# ET6801 register map
Vendor: ETMCU Inc.; File version: v0.0.1
CPU: CM7 r2p1, little endian, MPU, FPU, I-cache, D-cache, ITCM, DTCM, 4 interrupt priority bits
Registers are 32-bit, read-write, reset 0x0 unless marked. A register's access mark holds for its fields unless they carry their own. Offsets are from the block's base; [hi:lo] are bit positions; lines under a group give offsets from that group; {n}, {i} and the like mark numbered series.

## ADC0 — Provide an overview of the purpose and functionality of the peripheral: sarc_cfg
Base 0x40119000
Same registers: ADC1 0x4011A000, ADC2 0x4011B000
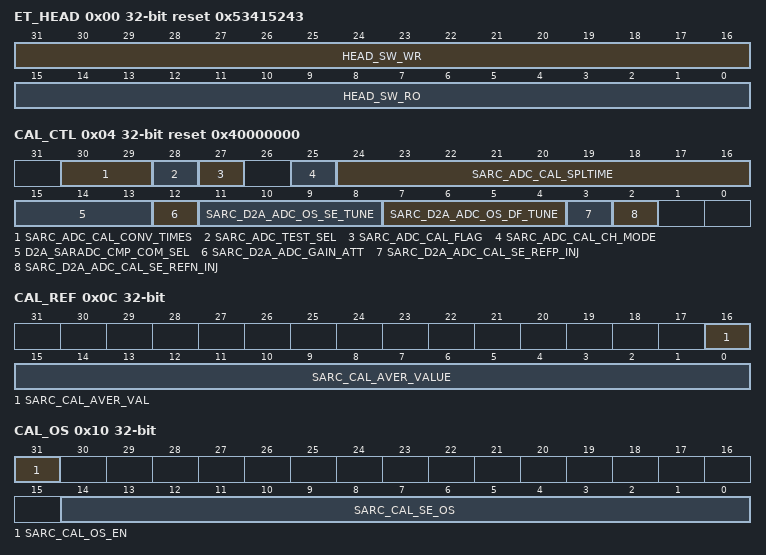
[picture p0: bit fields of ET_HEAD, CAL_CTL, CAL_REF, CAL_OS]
0x00 ET_HEAD reset 0x53415243
  [31:16] HEAD_SW_WR — 软件测试读写寄存器，硬件无访问
  [15:0] HEAD_SW_RO ro — 软件只读上报寄存器，硬件无访问,SARC的ASICII 码表示
0x04 CAL_CTL reset 0x40000000
  [30:29] SARC_ADC_CAL_CONV_TIMES — ADC校正时的模式选择。 'b00：1次转换结果上报； 'b01：8次转换结果平均后上报； 'b10：16次转换结果平均后上报； 'b11：32次转换结果平均后上报。
  [28] SARC_ADC_TEST_SEL — ADC测试模式选择。 'b 0：测试模式关闭 'b 1：测试模式打开，ADC测试模式包括（ADC测量模拟内部其他待观测节点电压，DAC校正时需要ADC对其输出信号检测等）
  [27] SARC_ADC_CAL_FLAG — ADC校正启动。此位由软件置1，用于开始ADC校准。在校正完成后，由软件置0。拉高该位后，再控制cfg_sarc_adc_cal_conv_start发起一轮校准采样。 'b 0：校准已完成。 'b 1：正在校准 ADC。
  [25] SARC_ADC_CAL_CH_MODE — 校正时，adccore的工作模式。 此位由软件置1和置0，用于配置校正时选择单端输入模式或差分输入模式。 0：单端输入模式。 1：差分输入模式。
  [24:16] SARC_ADC_CAL_SPLTIME — ADC CORE校正时，增加采样时长配置。ADCCLK时钟的周期计数。 配置值表示增加采样时长的时钟周期数；
  [15:13] D2A_SARADC_CMP_COM_SEL — SARADC0内部共模选择 3'b000：1.80V; 3'b001：1.65V; 3'b010：1.70V; 3'b011：1.75V; 3'b100：1.85V; 3'b101：1.90V; 3'b110：1.95V; 3'b111：2.00V;
  [12] SARC_D2A_ADC_GAIN_ATT — 配置ADC增益衰减为(1-32/4096)。 'b 0：默认ADC增益为1，即ADC输入为REFP-REFN时，输出为4096； 'b 1：使能校正时置为1，将ADC的增益衰减为(1-32/4096)。
  [11:8] SARC_D2A_ADC_OS_SE_TUNE — 配置单端模式下ADC offset模拟补偿值。 默认为全0，不做offset补偿。 1、Bit<3>为符号位，为1表示减，为0时表示加。 2、bit<2>对应8LSB，bit<1>对应4LSB，bit<0>对应2LSB。 3、例子： 0000/1000为加上或者减去0LSB。 1111为减去14LSB，0111为加上14LSB等等。
  [7:4] SARC_D2A_ADC_OS_DF_TUNE — 配置差分模式下ADC offset模拟补偿值。 默认为全0，不做offset补偿。 1、Bit<3>为符号位，为1表示减，为0时表示加。 2、bit<2>对应8LSB，bit<1>对应4LSB，bit<0>对应2LSB。 3、例子： 0000/1000为加上或者减去0LSB。 1111为减去14LSB，0111为加上14LSB等等。
  [3] SARC_D2A_ADC_CAL_SE_REFP_INJ — 控制ADC单端侧输入vrefp 默认为0，校正时配置为1，单端侧输入vrefp
  [2] SARC_D2A_ADC_CAL_SE_REFN_INJ — 控制ADC单端侧输入vrefn 默认为0，校正时配置为1，单端侧输入vrefn
0x08 CAL_CONV_CTL
  [0] SARC_ADC_CAL_CONV_START — 软件在校正转换参数配置完成后，启动转换。软件读返回0，软件写1启动转换。ADCCORE IDLE状态下，再cfg_sarc_adc_cal_flag 为高期间，拉高一次cfg_sarc_adc_cal_conv_start发起一轮ADC的转换。 'b 0：禁止校正转换； 'b 1：开始校正转换；
0x0C CAL_REF ro
  [16] SARC_CAL_AVER_VAL read-clears — 指示n次转换后的平均值有效。该寄存器在软件读取后自清零。 'b 0：平均值无效； 'b 1：平均值有效。
  [15:0] SARC_CAL_AVER_VALUE — n次转换后的平均值。S(16,2)。
0x10 CAL_OS
  [31] SARC_CAL_OS_EN — 数字域offset校正使能模块。 'b 0：数字域offset校正关闭。 'b 1：数字域offset校正打开。
  [14:0] SARC_CAL_SE_OS — 单端模式下数字域补偿的offset值，515bit有符号数，s(5,0) s(15,2) 精度1/4LSB。范围-16LSB---+15LSB
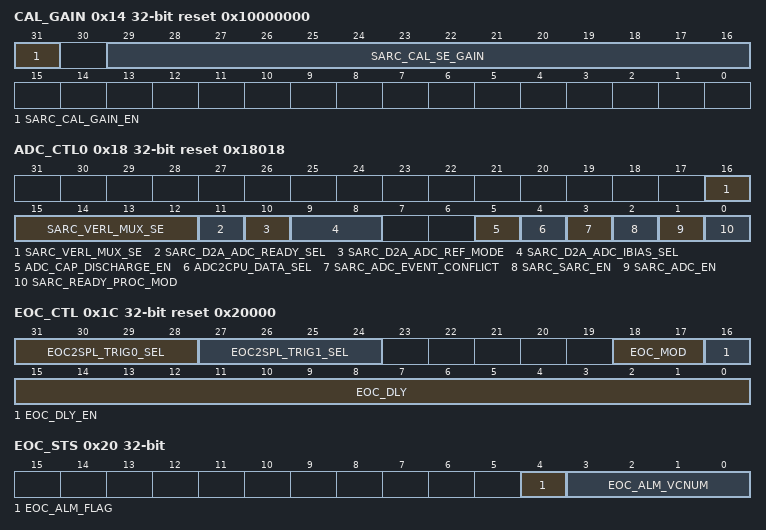
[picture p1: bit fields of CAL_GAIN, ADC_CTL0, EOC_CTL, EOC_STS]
0x14 CAL_GAIN reset 0x10000000
  [31] SARC_CAL_GAIN_EN — 数字域gain校正使能模块。 'b 0：数字域gain校正关闭。 'b 1：数字域gain校正打开。
  [29:16] SARC_CAL_SE_GAIN — 单端模式下数字域补偿的gain值，无符号数，u(14,12)
0x18 ADC_CTL0 reset 0x18018
  [16:12] SARC_VERL_MUX_SE — 放电过程中将mux切换到该值，使得模拟连接到VERFLO，默认0x18
  [11] SARC_D2A_ADC_READY_SEL — SARADC0 ready时序选择信号（模拟侧）， 1'b0：ready时序模拟顶层（AFE_TOP）对齐模式； 1'b1：ready时序模拟底层（ADC_CORE）对齐模式；
  [10] SARC_D2A_ADC_REF_MODE — SARADC参考电压模式选择 1'b0：参考电压为VREFHI（3.3V或2.5V），ADC输出摆幅为3.3V或2.5V; 1'b1：参考电压为1.65V，ADC输出摆幅为3.3V;
  [9:8] SARC_D2A_ADC_IBIAS_SEL — ADC bias电流调节 'b 00：5uA（默认值） 'b 01：3.75uA 'b 10：6.25uA 'b 11：7.5uA
  [5] ADC_CAP_DISCHARGE_EN — ADC启用放电功能配置 'b0:不启用放电功能； 'b1:启用放电功能；
  [4] ADC2CPU_DATA_SEL — adc内部同步到cpu_wrap的数据选择； 'b0：同步输出用户预处理通道结果到cpu_wrap 'b1：同步输出滤波通道结果到cpu_wrap
  [3] SARC_ADC_EVENT_CONFLICT — 事件冲突（多个虚拟通道同时触发采样）处理方式。 'b 0：低优先级任务被丢弃； 'b 1：低优先级任务排队处理。
  [2] SARC_SARC_EN — ADC控制器使能指示信号。 'b 0：ADC控制器不使能； 'b 1：ADC控制器使能。
  [1] SARC_ADC_EN — ADC core使能指示信号。 'b 0：ADC core不使能； 'b 1：ADC core使能。
  [0] SARC_READY_PROC_MOD — ADC READY处理模式选择配置（数字侧）。 'b 0：异步处理； 'b 1：同步处理。
0x1C EOC_CTL reset 0x20000
  [31:28] EOC2SPL_TRIG0_SEL — EOC事件输出1选择配置，从16个虚拟通道的EOC事件中选择1个作为ADC的采样触发源。 'd0：虚拟通道0的EOC事件； 'd1：虚拟通道1的EOC事件； ...... 'd15：虚拟通道15的EOC事件；
  [27:24] EOC2SPL_TRIG1_SEL — EOC事件输出2选择配置，从16个虚拟通道的EOC事件中选择1个作为ADC的采样触发源。 'd0：虚拟通道0的EOC事件； 'd1：虚拟通道1的EOC事件； ...... 'd15：虚拟通道15的EOC事件；
  [18:17] EOC_MOD — EOC产生时刻选择： 'b00：选择采样结束时刻，S/H窗口下降沿； 'b01：选择转换结束时刻，模拟ADC返回ready上升沿； 'b10: 选择采样开始时刻，S/H窗口上升沿,（内部状态仲裁出通道号后即给出，实际会比START信号早一点）； 'b11: reserved，同'b01；
  [16] EOC_DLY_EN — EOC选择时刻到中断上升沿是否延时的使能配置。 'b0：不使能延时，EOC时刻直接产生中断； 'b1：使能延时，在EOC时刻延时cfg_eoc_dly的SYSCLK周期后产生中断；
  [15:0] EOC_DLY — EOC选择时刻到中断上升沿的延时值配置，SYSCLK周期数。 实际延时值为该配置值加1，即cfg_eoc_dly+1。
0x20 EOC_STS ro
  [4] EOC_ALM_FLAG read-clears — 当eoc事件到达时，延时处理模块如果处于busy状态，则上报告警。 'b 0：无告警产生； 'b 1：有延时处理冲突告警；
  [3:0] EOC_ALM_VCNUM — 当eoc_alm_flag为高时，该域表示产生延时处理冲突的虚拟通道编号。 当eoc_alm_flag为低时，该域无效。 'd0~'d15对应表示虚拟通道0~15。
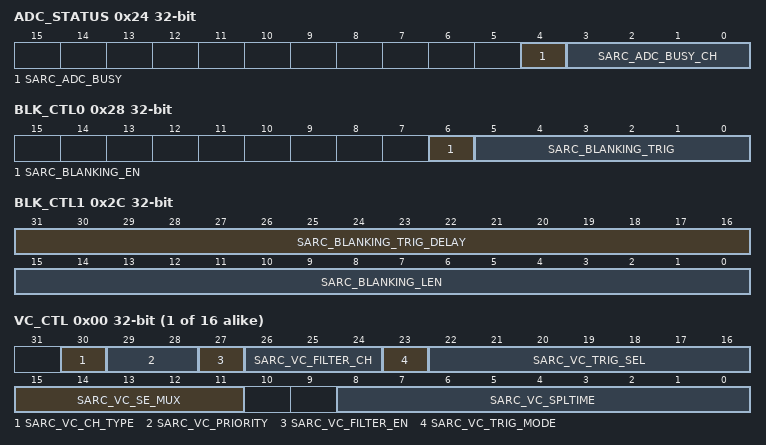
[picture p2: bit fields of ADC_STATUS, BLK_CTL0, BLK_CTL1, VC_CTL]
0x24 ADC_STATUS ro
  [4] SARC_ADC_BUSY — ADC采样busy状态。 ADC VC采样转换开始时置1，即busy； 虚拟通道VC采样转换完成后置0，即idle； 'b 0：IDLE； 'b 1：BUSY；
  [3:0] SARC_ADC_BUSY_CH — ADC busy通道指示。 adc_busy =0：保持上一个转换的VC通道号； adc_busy=1：指示当前正在转换操作的VC通道号；
0x28 BLK_CTL0
  [6] SARC_BLANKING_EN — ADC控制器的blanking功能使能标志。每个ADC控制器只有虚拟通道0（VC0）支持blanking管理功能。 'b 0：不使能； 'b 1：使能；
  [5:0] SARC_BLANKING_TRIG — ADC控制器的blanking触发源选择，该触发源触发blanking事件产生。Blanking支持64个触发源：
0x2C BLK_CTL1
  [31:16] SARC_BLANKING_TRIG_DELAY — ADC控制器的blanking延迟触发时间配置。SYSCLK时钟16bit计数器。配置值即为时钟周期数。 注意：在使能blanking功能时，该配置值需要大于0；
  [15:0] SARC_BLANKING_LEN — ADC控制器的blanking窗口长度配置。SYSCLK时钟16bit计数器。配置值即为时钟周期数。 注意： 1、在使能blanking功能时，该配置值需要大于0； 2、延迟时间和窗口长度配置时，需考虑将窗口提前打开，提前时间为一次转换时间。
0x30 VCEN_CTL
  [15:0] SARC_VC_EN — VC的使能信号,16bit分别表示16个VC的使能配置： 'b 0：不使能该VC； 'b 1：使能该VC；
{0x34+4i} VC_CTL[{i}] (i=0..15) group — CFG_SARC_VC_CTL
  0x00 VC_CTL
    [30] SARC_VC_CH_TYPE — VC采样通道类型选择： 0：单端模式； 1：差分模式；
    [29:28] SARC_VC_PRIORITY — VC的优先级指示。值越小优先级越高，同一优先级组中，VC的序号越小优先级越高。 'b 00：该VC处理第一优先级组； 'b 01：该VC处理第二优先级组； 'b 10：该VC处理第三优先级组； 'b 11：该VC处理第四优先级组；
    [27] SARC_VC_FILTER_EN — VC通道是否滤波。 'b 0：不滤波 'b 1：滤波
    [26:24] SARC_VC_FILTER_CH — VC通道与滤波通道的映射关系。 'b 000：映射滤波通道0； 'b 001：映射滤波通道1； ...... 'b 111：映射滤波通道7。
    [23] SARC_VC_TRIG_MODE — VCx的触发模式选择。支持One-Shot和Continuous两种触发模式。 'b 0：Continuous模式； 'b 1：One-Shot模式；
    [22:16] SARC_VC_TRIG_SEL — VCx的触发源选择。支持128个触发源选择。
    [15:11] SARC_VC_SE_MUX — VCx的单端转换通道选择。 'd0：通道0； 'd1：通道1； ...... 'd30：通道30； 'd31：通道31；
    [8:0] SARC_VC_SPLTIME — VCx的捕获预设。控制S/H增加的采样时间，支持0-256个ADCCLK周期数可配置。 实际的采样窗口总长度为：spltim+2.5UI
0x74 VC_STATUS ro
  [31:0] SARC_VC_STATUS — VC的状态指示。每2bit表示1个VC的状态，16个VC共需要32bit。 'b 00：idle； 'b 01：pending；当前VC处理排队等待状态。 'b 10：busy； 'b 11：无效状态RESERVED；
0x78 VC_FLAG ro
  [15:0] SARC_VC_FLAG — VCx待转换标志，在VC开始转换（start信号的上升沿）时硬件clear。 在同一cycle，如果set和clear同时有效，则响应set，因此ADC_VC_OVF寄存器的对应bit位不受影响。
0x7C VC_FORCE
  [15:0] SARC_VC_FORCE wo — VCx强制转换开始标志。该位写1会强制将ADC_VC_FLG寄存器的对应位置1，用于软件控制启动转换。该位写0无效，该位读返回为0。 在同一cycle，如果软件set此位，同时硬件clear ADC_VC_FLG寄存器的对应位，则ADC_VC_FLG寄存器对应位响应set，此时ADC_VC_OVF寄存器的对应bit位不受影响。
0x80 VC_OVF ro
  [15:0] SARC_VC_OVF — VCx转换溢出标志。指示VCx是否发生转换溢出事件。即当VCx正有待转换事件时，硬件又产生下一个转换事件。 该溢出指示不影响转换事件的处理，仅指明硬件触发的丢失。软件控制的ADC_VC_FRC对应位不影响该溢出标志位的值。
0x84 VC_OVF_CLR
  [15:0] SARC_VC_OVF_CLR wo — VCx清除转换溢出标志。 该位写1清除ADC_VC_OVF中对应位的溢出标志，该位写0无效。该位读返回0。 当软件置1该位的操作，与硬件置1 ADC_VC_OVF寄存器中的对应位的操作在同一个cycle发生时，硬件优先级高，即ADC_VC_OVF寄存器对应位会被置1。
0x88 T2S_FR_CNT ro
  [11:0] T2S_FR_CNT — FREE-RUN计数器，当cfg_sarc_en有效时计数。该计数器用于trig-to-sample的延时捕获计数。
{0x8C+8i} T2S_STAMP[{i}] (i=0..15) group
  0x00 REQ ro
    [11:0] REQSTAMP — 采样触发到达时刻的时间戳，在采样触发到达时刻锁存FR_CNT计数值。
  0x04 DLY ro
    [11:0] DLYSTAMP — trig-to-sample的延时时间戳。 使用采样开始时刻（S/H窗口上升沿）FR_CNT的计数值，减去采样触发时刻的时间戳reqstamp。 注意：FR_CNT最大计数为4096，当trig-to-sample的延时超过4096时，该dlystamp上报值可能是错误值，应用时要避免该情况出现。
0x10C PRE_OS_EN
  [15:0] SARC_PRE_OS_EN — 预处理阶段offset系数使能模块。bit15-0对应vc15-0。 'b 0：预处理阶段offset校正关闭。 'b 1：预处理阶段offset校正打开。
{0x110+4i} PRE_OS[{i}] (i=0..15) group — CFG_SARC_PRE_OS
  0x00 PRE_OS
    [15:0] SARC_PRE_OS — 预处理通道补偿的offset值，16bit有符号数s(16,2)。 配置限制范围：16'ha000~16'h6003
0x150 PRE_GAIN_EN
  [15:0] SARC_PRE_GAIN_EN — 预处理阶段gain系数使能模块。bit15-0对应vc15-0。 'b 0：预处理阶段offset校正关闭。 'b 1：预处理阶段offset校正打开。
{0x154+4i} PRE_GAIN[{i}] (i=0..15) group — CFG_SARC_PRE_GAIN
  0x00 PRE_GAIN reset 0x1000
    [14:0] SARC_PRE_GAIN — 预处理通道的gain值，15bit有符号数s(15,12)。
0x194 WDT_CTL
  [15:0] WDT_MOD — 16个超门限检测通道输出方式选择，bit0-bit15分别指示通道0-15。 'b 0：ONE-SHOT； 'b 1：CBC；
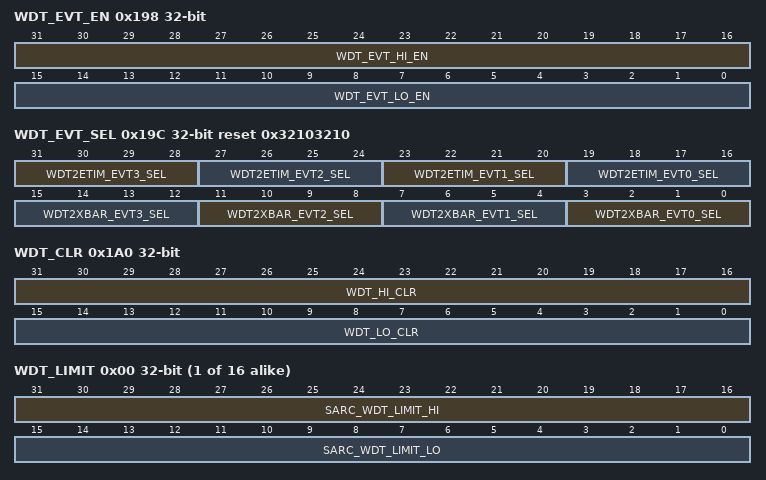
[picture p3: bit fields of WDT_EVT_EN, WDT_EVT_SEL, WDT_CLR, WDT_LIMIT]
0x198 WDT_EVT_EN
  [31:16] WDT_EVT_HI_EN — 16个超上门限事件输出使能，bit0-bit15分别指示通道0-15。 'b 0：不使能输出； 'b 1：使能输出；
  [15:0] WDT_EVT_LO_EN — 16个超下门限事件输出使能，bit0-bit15分别指示通道0-15。 'b 0：不使能输出； 'b 1：使能输出；
0x19C WDT_EVT_SEL reset 0x32103210
  [31:28] WDT2ETIM_EVT3_SEL — sarc2etim输出事件3的选择配置。 'd0~'d15：事件3输出选择虚拟通道0~15的事件；
  [27:24] WDT2ETIM_EVT2_SEL — sarc2etim输出事件2的选择配置。 'd0~'d15：事件22输出选择虚拟通道0~15的事件；
  [23:20] WDT2ETIM_EVT1_SEL — sarc2etim输出事件1的选择配置。 'd0~'d15：事件1输出选择虚拟通道0~15的事件；
  [19:16] WDT2ETIM_EVT0_SEL — sarc2etim输出事件0的选择配置。 'd0~'d15：事件0输出选择虚拟通道0~15的事件；
  [4n+3:4n] WDT2XBAR_EVT{n}_SEL (n=0..3) — sarc2xbar输出事件{n}的选择配置。 'd0~'d15：事件{n}输出选择虚拟通道0~15的事件；
0x1A0 WDT_CLR
  [31:16] WDT_HI_CLR wo — 16个超上门限状态清除指示，bit0-bit15分别指示通道0-15。 'b 0：无意义； 'b 1：产生清除脉冲；
  [15:0] WDT_LO_CLR wo — 16个超下门限状态清除指示，bit0-bit15分别指示通道0-15。 'b 0：无意义； 'b 1：产生清除脉冲；
{0x1A4+4i} WDT_LIMIT[{i}] (i=0..15) group — CFG_SARC_WDT_LIMIT
  0x00 WDT_LIMIT
    [31:16] SARC_WDT_LIMIT_HI — 预处理通道的WDT门限上限值。s(16,2)16bit有符号数
    [15:0] SARC_WDT_LIMIT_LO — 预处理通道的WDT门限下限值。s(16,2)16bit有符号数
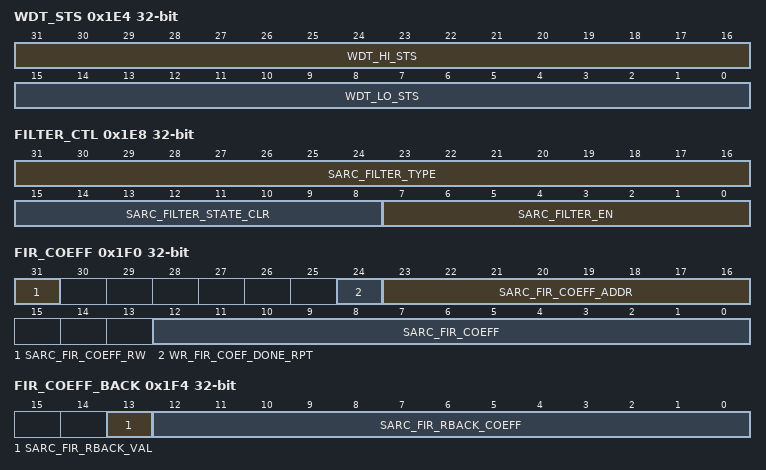
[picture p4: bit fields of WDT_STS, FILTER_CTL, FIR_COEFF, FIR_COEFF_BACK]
0x1E4 WDT_STS ro
  [31:16] WDT_HI_STS — 16个超上门限状态指示0-bit15分别指示通道0-15。 'b 0：无超上门限事件发生； 'b 1：有超上门限事件发生；
  [15:0] WDT_LO_STS — 16个超下门限状态指示，bit0-bit15分别指示通道0-15。 'b 0：无超下限事件发生； 'b 1：有超下限事件发生；
0x1E8 FILTER_CTL
  [31:16] SARC_FILTER_TYPE — 8个滤波通道类型选择，每个通道2bit表示类型选择。bit17-bit16指示滤波通道0的类型，...bit31-bit30指示滤波通道7的类型。 'b 00：FIR； 'b 01：IIR； 'b 10：非滑动平均； 'b 11：无效；
  [15:8] SARC_FILTER_STATE_CLR wo — 软件写1清除对应滤波通道状态，软件写0无效。bit15-bit8分别对应滤波通道7-滤波通道0。 建议在开启一轮新的滤波功能前，使用该控制位对滤波器进行清除，防止滤波历史残留数据对新数据的滤波产生影响。
  [7:0] SARC_FILTER_EN — 8个滤波通道使能信号，bit0-bit7分别指示滤波通道0-7。 'b 0：不使能； 'b 1：使能；
0x1EC NOAVER_COEFF
  [31:0] SARC_NOAVER_COEFF — 滤波通道7-0在非滑动平均滤波模式下的工作系数。每个通道4bit。 指示该滤波通道的平均次数：2^n ,n为该配置值。
0x1F0 FIR_COEFF
  [31] SARC_FIR_COEFF_RW — 软件操作滤波器系数的读写指示。 'b 0：write； 'b 1：read；
  [24] WR_FIR_COEF_DONE_RPT ro read-clears — 滤波器系数值配置完成上报信号。如果在滤波器通道工作过程中需要改变未使能的滤波通道的系数，该寄存器作为软件和硬件交互的接口，每次配置完成后软件需要读取该寄存器确定配置完成后，才能配置下一个系数。因为滤波器通道中读系数的优先级大于写系数的优先级。 'd0：滤波器系数没有配置，或者配置没有完成，或者配置完成被软件读清了 'd1：滤波器系数配置完成
  [23:16] SARC_FIR_COEFF_ADDR — 软件操作滤波器系数的地址数据。1个ADC控制器共有8组fir和iir滤波系数，FIR滤波器每组32个13bit有符号数s(13,12)，IIR滤波器每组1个13bit有符号数s(13,12)。 'b 000 00000-'b 000 11111：滤波通道0的FIR系数，共32个； 'b 001 00000-'b 001 11111：滤波通道1的FIR系数，共32个； 'b 010 00000-'b 010 11111：滤波通道2的FIR系数，共32个； 'b 011 00000-'b 011 11111：滤波通道3的FIR系数，共32个； 'b 100 00000-'b 100 11111：滤波通道4的FIR系数，共32个； 'b 101 00000-'b 101 11111：滤波通道5的FIR系数，共32个； 'b 110 00000-'b 110 11111：滤波通道6的FIR系数，共32个； 'b 111 00000-'b 111 11111：滤波通道7的FIR系数，共32个；
  [12:0] SARC_FIR_COEFF — 软件配置滤波器系数值，13bit有符号数。滤波系数固定为s(13,12)
0x1F4 FIR_COEFF_BACK ro
  [13] SARC_FIR_RBACK_VAL read-clears — 软件回读fir系数值有效指示。
  [12:0] SARC_FIR_RBACK_COEFF — 软件回读fir系数值，13bit有符号数。滤波系数固定为s(13,12)
{0x1F8+4i} FIR_LENGTH[{i}] (i=0..7) group — CFG_FIR_LENGTH
  0x00 FIR_LEN reset 0x1F
    [4:0] FIR_LEN — fir滤波器阶数配置，最大32阶。默认配置32阶。 'd0：1阶fir滤波； 'd1：2阶fir滤波； 'd2：3阶fir滤波； ...... 'd31：32阶fir滤波；
{0x218+4i} IIR_COEFF[{i}] (i=0..7) group — CFG_SARC_IIR_COEFF
  0x00 IIR_COEFF
    [12:0] SARC_IIR_COEFF — iir滤波器通道的滤波系数alpha，13bit有符号数s(13,12)，0 ≤ alpha ≤ 1
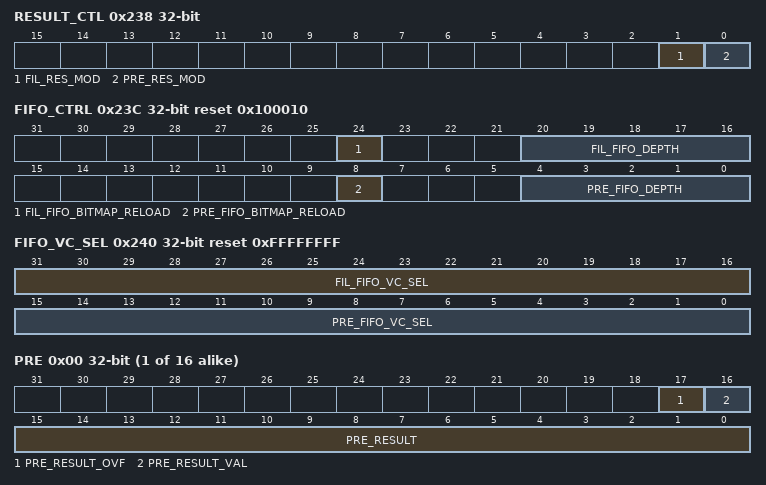
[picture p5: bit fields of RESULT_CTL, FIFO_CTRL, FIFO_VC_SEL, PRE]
0x238 RESULT_CTL
  [1] FIL_RES_MOD — ADC采样值滤波后上报结果寄存器格式配置： 'd0：u(12,0) 'd1：s(16,2)
  [0] PRE_RES_MOD — ADC采样值用户预处理后上报结果寄存器格式配置： 'd0：s(15,0)该数据由s(16,2)格式数据四舍五入后得到； 'd1：s(16,2)
0x23C FIFO_CTRL reset 0x100010
  [24] FIL_FIFO_BITMAP_RELOAD wo — ADC采样值滤波后上报结果采用fifo模式读取时，fifo读数据地址重新加载指示信号。在软件初始化或者重新配置vc_en/fifo_vc_sel后，需要向该bit位写1。 'b0：重新加载指示无效 'b1：重新加载指示有效
  [20:16] FIL_FIFO_DEPTH — ADC采样值滤波后上报结果采用fifo模式读取时，fifo的深度配置： 'd0：fifo深度为0，无效配置 'd1：fifo深度为1 'd2：fifo深度为2 ... 'd16：fifo深度为16 其它：无效配置
  [8] PRE_FIFO_BITMAP_RELOAD wo — ADC采样值用户预处理后上报结果采用fifo模式读取时，fifo读数据地址重新加载指示信号。在软件初始化或者重新配置vc_en/fifo_vc_sel后，需要向该bit位写1。 'b0：重新加载指示无效 'b1：重新加载指示有效
  [4:0] PRE_FIFO_DEPTH — ADC采样值用户预处理后上报结果采用fifo模式读取时，fifo的深度配置： 'd0：fifo深度为0，无效配置 'd1：fifo深度为1 'd2：fifo深度为2 ... 'd16：fifo深度为16 其它：无效配置
0x240 FIFO_VC_SEL reset 0xFFFFFFFF
  [31:16] FIL_FIFO_VC_SEL — ADC采样值滤波后上报结果采用fifo模式读取时，fifo映射vc选择配置，默认为全1，该配置与cfg_vc_en相与后作为最终的映射关系。如果使能的vc都映射到fifo时，该寄存器可以使用默认配置： 'b0：对应vc不映射到fifo模式 'b1：对应vc映射到fifo模式
  [15:0] PRE_FIFO_VC_SEL — ADC采样值用户预处理后上报结果采用fifo模式读取时，fifo映射vc选择配置，默认为全1，该配置与cfg_vc_en相与后作为最终的映射关系。如果使能的vc都映射到fifo时，该寄存器可以使用默认配置： 'b0：对应vc不映射到fifo模式 'b1：对应vc映射到fifo模式
0x244 FIL_FIFO_STS ro
  [31:0] FIL_FIFO_STS — ADC采样值滤波后上报结果采用fifo模式读取时，fifo的状态上报指示： bit0：fifo_full （fifo满） bit1：fifo_empty（fifo空） bit2：fifo_full_ovf（fifo满溢出） bit3：fifo_empty_ovf（fifo空溢出） bit4-bit8：fifo_data_cnt（fifo数据个数） 其它bit：无效
0x248 PRE_FIFO_STS ro
  [31:0] PRE_FIFO_STS — ADC采样值用户预处理后上报结果采用fifo模式读取时，fifo的状态上报指示： bit0：fifo_full （fifo满） bit1：fifo_empty（fifo空） bit2：fifo_full_ovf（fifo满溢出） bit3：fifo_empty_ovf（fifo空溢出） bit4-bit8：fifo_data_cnt（fifo数据个数） 其它bit：无效
0x24C FIL_FIFO_DATA ro
  [31:0] FIL_FIFO_DATA — ADC采样值滤波后上报结果采用fifo模式读取时，fifo的数据上报： bit0-bit15：采样结果 bit16：采样结果val值 bit17：采样结果ovf值 bit18-bit21：采样结果对应的vc编号 其它bit：无效
0x250 PRE_FIFO_DATA ro
  [31:0] PRE_FIFO_DATA — ADC采样值用户预处理后上报结果采用fifo模式读取时，fifo的数据上报： bit0-bit15：采样结果 bit16：采样结果val值 bit17：采样结果ovf值 bit18-bit21：采样结果对应的vc编号 其它bit：无效
{0x254+4i} PRE_RESULT[{i}] (i=0..15) group
  0x00 PRE
    [17] PRE_RESULT_OVF — VC采样结果寄存器有数据溢出指示。读清零。 每次有采样数据到达到，如果adc_result_val信号为高，则产生溢出指示。
    [16] PRE_RESULT_VAL — VC采样结果寄存器有数据指示。读清零。 每次该VC有采样数据，val信号置高。CPU或DMA读走后，置低。
    [15:0] PRE_RESULT ro — VC采样结果寄存器，s(15,0) (最高2位[15:14]均为符号位)或者s(16,2)
{0x294+4i} FIL_RESULT[{i}] (i=0..15) group
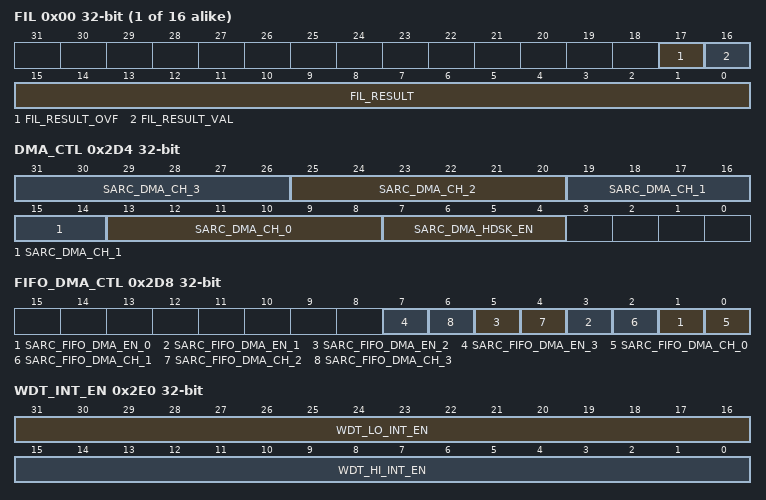
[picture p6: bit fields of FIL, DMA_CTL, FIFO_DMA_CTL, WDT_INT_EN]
  0x00 FIL
    [17] FIL_RESULT_OVF — VC采样结果寄存器有数据溢出指示。读清零。 每次有采样数据到达到，如果adc_result_val信号为高，则产生溢出指示。
    [16] FIL_RESULT_VAL — VC采样结果寄存器有数据指示。读清零。 每次该VC有采样数据，val信号置高。CPU或DMA读走后，置低。
    [15:0] FIL_RESULT ro — VC采样结果寄存器，u(12,0)或者s(16,2)
0x2D4 DMA_CTL
  [6n+13:6n+8] SARC_DMA_CH_{n} (n=0..3) — DMA通道{n}的选择。从64bit的DMA请求中选取1bit。 bit63-bit48：滤波后结果更新（vc15-vc0）； bit47-bit32：用户预处理后结果更新（vc15-vc0）； bit31-bit16：ADC超门限告警（超上下门限相或）（vc15-vc0）； bit15-bit0： ADC EOC（vc15-vc0）；
  [7:4] SARC_DMA_HDSK_EN — 4个DMA通道的握手模块使能信号。 'b 0：不使能； 'b 1：使能； 该使能信号不使用，DMA的握手功能移到DMA_MUX模块中。
0x2D8 FIFO_DMA_CTL
  [2n+1] SARC_FIFO_DMA_EN_{n} (n=0..3) — DMA通道{n}是否选择fifo请求使能配置 'b 0：不选择fifo请求，通道{n}的请求由CFG_SARC_DMA_CTL控制； 'b 1：选择fifo请求，由cfg_sarc_fifo_dma_ch_{n}选择相应的fifo请求；
  [2n] SARC_FIFO_DMA_CH_{n} (n=0..3) — DMA通道{n}选择fifo请求时，选择信号配置。只有cfg_sarc_fifo_dma_en_{n}为1时，才能选择对应的fifo请求到DMA通道{n}。 'b 0：选择pre_fifo的请求； 'b 1：选择fil_fifo的请求；
0x2DC EOC_INT_EN
  [3:0] EOC_INT_EN — ADC EOC中断使能信号，bit0~bit3分别表示eoc0~3 'b 0：不使能中断；'b 1：使能中断；
0x2E0 WDT_INT_EN
  [31:16] WDT_LO_INT_EN — ADC 采样超下门限中断使能信号，bit0~bit15分别表示虚拟通道0~15。 'b 0：不使能中断；'b 1：使能中断；
  [15:0] WDT_HI_INT_EN — ADC 采样超上门限中断使能信号，bit0~bit15分别表示虚拟通道0~15。 'b 0：不使能中断；'b 1：使能中断；
0x2E4 EOC_INT_MASK
  [3:0] EOC_INT_MASK — ADC 选择后EOC中断屏蔽信号，bit0~bit3分别表示eoc0~eoc3 'b 0：不屏蔽中断；'b 1：屏蔽中断；
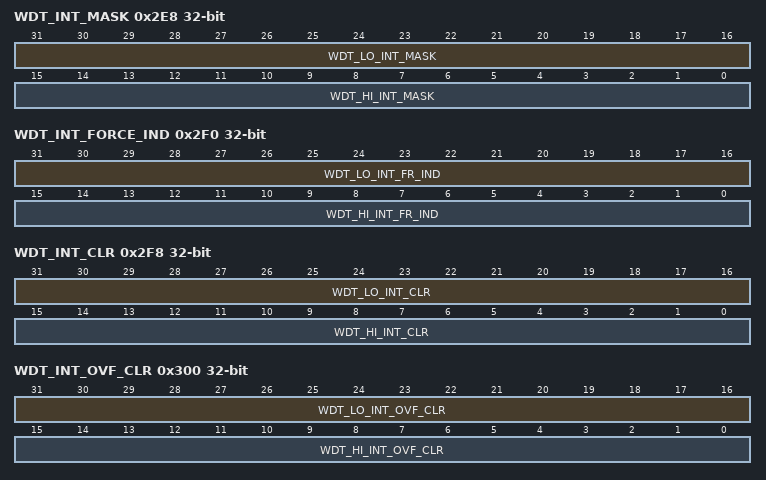
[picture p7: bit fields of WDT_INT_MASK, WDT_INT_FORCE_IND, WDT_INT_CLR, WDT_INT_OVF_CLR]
0x2E8 WDT_INT_MASK
  [31:16] WDT_LO_INT_MASK — ADC 采样超下门限中断屏蔽信号，bit0~bit15分别表示虚拟通道0~15。 'b 0：不屏蔽中断；'b 1：屏蔽中断；
  [15:0] WDT_HI_INT_MASK — ADC 采样超上门限中断屏蔽信号，bit0~bit15分别表示虚拟通道0~15。 'b 0：不屏蔽中断；'b 1：屏蔽中断；
0x2EC EOC_INT_FORCE_IND
  [3:0] EOC_INT_FR_IND — ADC EOC中断测试脉冲信号，bit0~bit3分别表示eoc0~eoc3 'b 0：不产生测试脉冲信号；'b 1：产生测试脉冲信号；
0x2F0 WDT_INT_FORCE_IND
  [31:16] WDT_LO_INT_FR_IND — ADC 采样超下门限中断测试脉冲信号，bit0~bit15分别表示虚拟通道0~15。 'b 0：不产生测试脉冲信号；'b 1：产生测试脉冲信号；
  [15:0] WDT_HI_INT_FR_IND — ADC 采样超上门限中断测试脉冲信号，bit0~bit15分别表示虚拟通道0~15。 'b 0：不产生测试脉冲信号；'b 1：产生测试脉冲信号；
0x2F4 EOC_INT_CLR
  [3:0] EOC_INT_CLR — ADC EOC中断清除脉冲信号，bit0~bit3分别表示eoc0~3 'b 0：不清除中断；'b 1：清除中断；
0x2F8 WDT_INT_CLR
  [31:16] WDT_LO_INT_CLR — ADC 采样超下门限中断清除脉冲信号，bit0~bit15分别表示虚拟通道0~15。 'b 0：不清除中断；'b 1：清除中断；
  [15:0] WDT_HI_INT_CLR — ADC 采样超上门限中断清除脉冲信号，bit0~bit15分别表示虚拟通道0~15。 'b 0：不清除中断；'b 1：清除中断；
0x2FC EOC_INT_OVF_CLR
  [3:0] EOC_INT_OVF_CLR — ADC EOC中断溢出指示清除脉冲信号，bit0~bit3分别表示虚拟通道eoc0~3 'b 0：不清除中断溢出指示；'b 1：清除中断溢出指示；
0x300 WDT_INT_OVF_CLR
  [31:16] WDT_LO_INT_OVF_CLR — ADC 采样超下门限中断溢出指示清除脉冲信号，bit0~bit15分别表示虚拟通道0~15。 'b 0：不清除中断溢出指示；'b 1：清除中断溢出指示；
  [15:0] WDT_HI_INT_OVF_CLR — ADC 采样超上门限中断溢出指示清除脉冲信号，bit0~bit15分别表示虚拟通道0~15。 'b 0：不清除中断溢出指示；'b 1：清除中断溢出指示；
0x304 EOC_INT_STS ro
  [3:0] EOC_INT_STS — ADC EOC中断状态指示（屏蔽后），bit0~bit3分别表示eoc0~3 'b 0：无中断指示；'b 1：有中断指示；
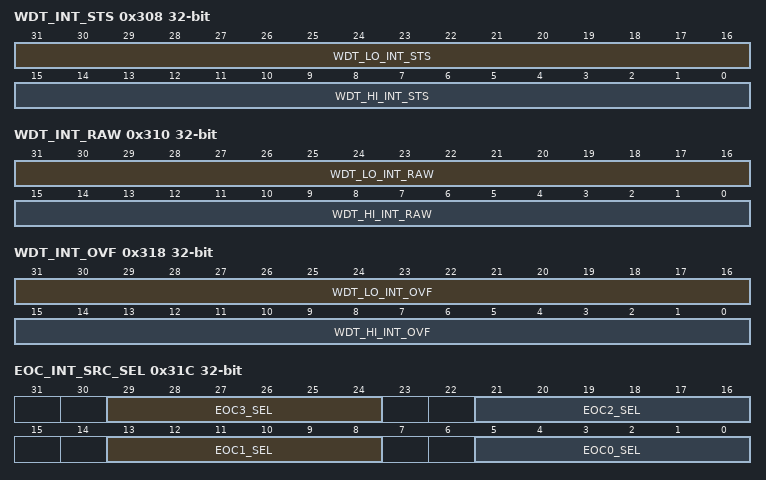
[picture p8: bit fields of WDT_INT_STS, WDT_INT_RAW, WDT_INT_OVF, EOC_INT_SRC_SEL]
0x308 WDT_INT_STS ro
  [31:16] WDT_LO_INT_STS — ADC 采样超下门限中断状态指示（屏蔽后），bit0~bit15分别表示虚拟通道0~15。 'b 0：无中断指示；'b 1：有中断指示；
  [15:0] WDT_HI_INT_STS — ADC 采样超上门限中断状态指示（屏蔽后），bit0~bit15分别表示虚拟通道0~15。 'b 0：无中断指示；'b 1：有中断指示；
0x30C EOC_INT_RAW ro
  [3:0] EOC_INT_RAW — ADC EOC中断原始状态指示（屏蔽前），bit0~bit3分别表示eoc0~3 'b 0：无中断指示；'b 1：有中断指示；
0x310 WDT_INT_RAW ro
  [31:16] WDT_LO_INT_RAW — ADC 采样超下门限中断原始状态指示（屏蔽前），bit0~bit15分别表示虚拟通道0~15。 'b 0：无中断指示；'b 1：有中断指示；
  [15:0] WDT_HI_INT_RAW — ADC 采样超上门限中断原始状态指示（屏蔽前），bit0~bit15分别表示虚拟通道0~15。 'b 0：无中断指示；'b 1：有中断指示；
0x314 EOC_INT_OVF ro
  [3:0] EOC_INT_OVF — ADC EOC中断溢出指示，bit0~bit3分别表示虚拟通道eoc0~3 'b 0：无中断溢出；'b 1：中断溢出；
0x318 WDT_INT_OVF ro
  [31:16] WDT_LO_INT_OVF — ADC 采样超下门限中断溢出指示，bit0~bit15分别表示虚拟通道0~15。 'b 0：无中断溢出；'b 1：中断溢出；
  [15:0] WDT_HI_INT_OVF — ADC 采样超上门限中断溢出指示，bit0~bit15分别表示虚拟通道0~15。 'b 0：无中断溢出；'b 1：中断溢出；
0x31C EOC_INT_SRC_SEL
  [29:24] EOC3_SEL — 选择eoc3的中断触发源，选择列表同cfg_eoc0_sel
  [21:16] EOC2_SEL — 选择eoc2的中断触发源，选择列表同cfg_eoc0_sel
  [13:8] EOC1_SEL — 选择eoc1的中断触发源，选择列表同cfg_eoc0_sel
  [5:0] EOC0_SEL — d0~'d15:选择eoc_out_p[0]~eoc_out_p[15]作为eoc0的中断源 'd16~'d31: 选择pre_result_in_enb[0]~pre_result_in_enb[15]作为eoc0的中断源 'd32~47: 选择fil_result_in_enb [0]~fil_result_in_enb[15]作为eoc0的中断源 other：reserved
{0x320+4i} DEBUG[{i}] (i=0..1) group — CFG_SARC_DEBUG
  0x00 DEBUG ro
    [31:0] SARC_DEBUG_INFO — Bit63-bit0: 20'h0, Cal_state_flag, Cal_curst[1:0], Cal_nxtst[1:0], Calf_curst[2:0], Calf_nxtst[2:0], Aver_curst[1:0], Aver_nxtst[1:0], Cal_conv_mode[1:0], Cal_conv_done, Cal_aver_done, Sum_done, Adc_en_cal, None_flag, Vc_trig_en[15:0], Sample_curst[1:0], Sample_nxtst[1:0], Spl_curst, Spl_nxtst;
{0x328+4i} PC_GRP[{i}] (i=0..15) group
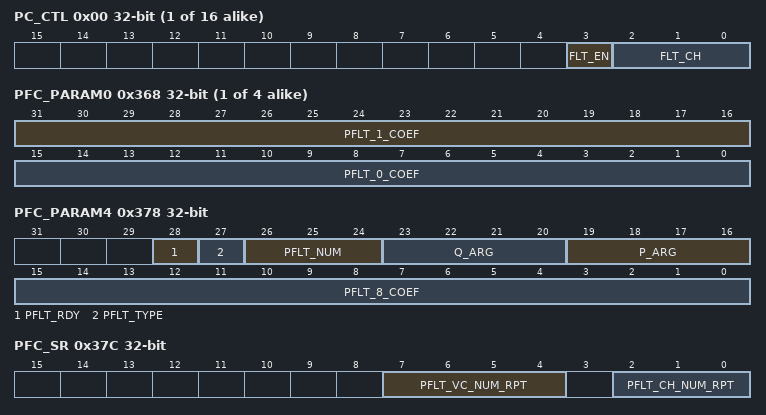
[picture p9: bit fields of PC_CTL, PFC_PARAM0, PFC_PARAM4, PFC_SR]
  0x00 PC_CTL
    [3] FLT_EN — 预处理通道通道是否滤波。 'd0：不滤波 'd1：滤波
    [2:0] FLT_CH — 预处理通道与预处理滤波通道的映射关系。 'd0：映射预处理滤波通道0； 'd1：映射预处理滤波通道1； ...... 'd7：映射预处理滤波通道7。
{0x368+4i} PFC_PARAM{i} (i=0..3)
  [31:16] PFLT_{2i+1}_COEF — 预处理滤波器系数{2i+1}，影子寄存器
  [15:0] PFLT_{2i}_COEF — 预处理滤波器系数{2i}，影子寄存器
0x378 PFC_PARAM4
  [28] PFLT_RDY — 预处理滤波器系数系数准备好，当对应通道的滤波器配置好之后，硬件会将该bit信号清零 'd0：滤波器系数未准备好； 'd1：滤波器系数准备好；
  [27] PFLT_TYPE — 预处理滤波器类型，影子寄存器 'd0：fir滤波器； 'd1：iir滤波器；
  [26:24] PFLT_NUM — 配置预处理滤波器的通道号 'd0：配置预处理滤波通道0的系数； 'd1：配置预处理滤波通道1的系数； ...... 'd7：配置预处理滤波通道7的系数。
  [23:20] Q_ARG — 预处理滤波器反馈系数的个数，影子寄存器
  [19:16] P_ARG — 预处理滤波器前馈系数的个数，影子寄存器
  [15:0] PFLT_8_COEF — 预处理滤波器系数8，影子寄存器
0x37C PFC_SR ro
  [7:4] PFLT_VC_NUM_RPT — 当前正在使用预处理滤波器的预处理通道号
  [2:0] PFLT_CH_NUM_RPT — 当前正在使用的预处理滤波器通道号
{0x380+0x18*i} PFC_GRP[{i}] (i=0..7) group
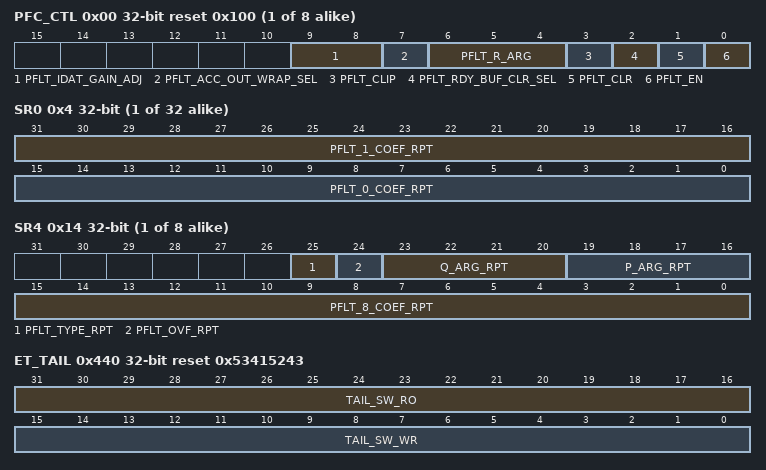
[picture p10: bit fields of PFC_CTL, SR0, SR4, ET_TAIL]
  0x00 PFC_CTL reset 0x100
    [9:8] PFLT_IDAT_GAIN_ADJ — 预处理滤波器输入数据增益调整 'd0：x2。 'd1：x1。 'd2：/2。 'd3：/4。
    [7] PFLT_ACC_OUT_WRAP_SEL — 累加器的输出是否做wrap 'd0：累加器的输出不做wrap，做saturate，超过s(16,15)范围的累加器输出的值，根据符号饱和到最大正负值(+((2^15-1)/ 2^15) 或 -1)。 'd1：累加器的输出做wrap。累加器结果超过s(16,15)范围的值将wrap。
    [6:4] PFLT_R_ARG — 预处理滤波器输出增益调整，放大2^r倍
    [3] PFLT_CLIP — 预处理滤波器累加结果是否修剪 'd0:关闭修剪。累加器结果超过s(26,22)范围的值将wrap。 'd1:启用修剪。超过s(26,22)范围的累加器输出的值，根据符号饱和到最大正负值(+((2^25-1)/ 2^25) 或 -1)。
    [2] PFLT_RDY_BUF_CLR_SEL — 预处理通道通道更新滤波器系数时是否清除输入数据缓存。 'd0：不清除； 'd1：清除；
    [1] PFLT_CLR — 预处理滤波器通道清除滤波器输入数据缓存。 'd0：不清除； 'd1：清除；
    [0] PFLT_EN — 预处理滤波通道使能。 'd0：预处理滤波通道使能关闭； 'd1：预处理滤波通道使能打开；
  {0x4+4j} SR{j} ro (j=0..3)
    [31:16] PFLT_{2j+1}_COEF_RPT — 预处理滤波器系数{2j+1}
    [15:0] PFLT_{2j}_COEF_RPT — 预处理滤波器系数{2j}
  0x14 SR4 ro
    [25] PFLT_TYPE_RPT — 预处理滤波器类型 'd0：fir滤波器； 'd1：iir滤波器；
    [24] PFLT_OVF_RPT read-clears — 预处理滤波器累加器溢出
    [23:20] Q_ARG_RPT — 预处理滤波器反馈系数的个数
    [19:16] P_ARG_RPT — 预处理滤波器前馈系数的个数
    [15:0] PFLT_8_COEF_RPT — 预处理滤波器系数8
0x440 ET_TAIL reset 0x53415243
  [31:16] TAIL_SW_RO ro — 软件测试读写寄存器，硬件无访问
  [15:0] TAIL_SW_WR — 软件只读上报寄存器，硬件无访问,SARC的ASICII 码表示
